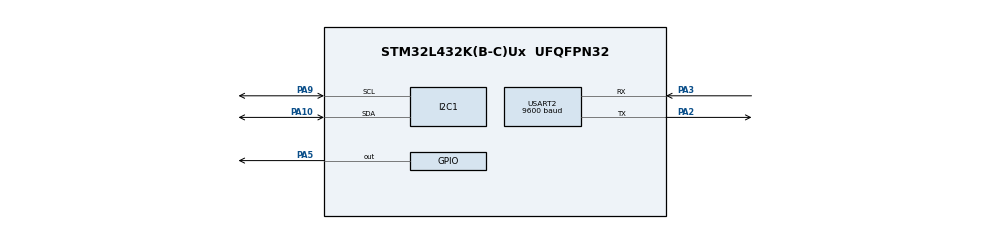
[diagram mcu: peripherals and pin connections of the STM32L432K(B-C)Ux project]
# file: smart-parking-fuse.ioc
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Mcu.Family=STM32L4
Mcu.Name=STM32L432K(B-C)Ux
Mcu.Package=UFQFPN32
NVIC.PriorityGroup=NVIC_PRIORITYGROUP_4
NVIC.USART2_IRQn=true\:0\:0\:false\:false\:true\:true\:true
PA10.Mode=I2C
PA10.Signal=I2C1_SDA
PA2.Mode=Asynchronous
PA2.Signal=USART2_TX
PA3.Mode=Asynchronous
PA3.Signal=USART2_RX
PA5.Signal=GPIO_Output
PA9.Mode=I2C
PA9.Signal=I2C1_SCL
ProjectManager.HeapSize=0x200
ProjectManager.StackSize=0x400
ProjectManager.TargetToolchain=Makefile
RCC.HSE_VALUE=8000000
RCC.HSI48_VALUE=48000000
RCC.HSI_VALUE=16000000
RCC.LSE_VALUE=32768
RCC.MSI_VALUE=4000000
RCC.VCOOutputFreq_Value=32000000
USART2.BaudRate=9600
USART2.VirtualMode-Asynchronous=VM_ASYNC
board=custom

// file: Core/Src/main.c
/**
  ******************************************************************************
  * @file           : main.c
  * @brief          : Main program body
  ******************************************************************************
  * @attention
  *
  * <h2><center>&copy; Copyright (c) 2021 STMicroelectronics.
  * All rights reserved.</center></h2>
  *
  * This software component is licensed by ST under BSD 3-Clause license,
  * the "License"; You may not use this file except in compliance with the
  * License. You may obtain a copy of the License at:
  *                        opensource.org/licenses/BSD-3-Clause
  *
  ******************************************************************************
  */
#include <stdio.h>
#include <string.h>

#include "main.h"
#include "uart.h"

#include <mma8451.h>

I2C_HandleTypeDef hi2c1;

UART_HandleTypeDef huart2;

void SystemClock_Config(void);
static void MX_GPIO_Init(void);
static void MX_I2C1_Init(void);
void MX_USART2_UART_Init(void);

void serial_write(uint8_t* msg, uint32_t size) {
    HAL_UART_Transmit(&huart2, msg, size, 100);
}

int main(void)
{
  /* Reset of all peripherals, Initializes the Flash interface and the Systick. */
  HAL_Init();

  /* Configure the system clock */
  SystemClock_Config();

  /* Initialize all configured peripherals */
  MX_GPIO_Init();
  MX_I2C1_Init();
  MX_USART2_UART_Init();

  setbuf(stdout, NULL);

  mma8451_t mma;
  memset(&mma, 0, sizeof(mma8451_t));

  HAL_GPIO_WritePin(GPIOA, GPIO_PIN_5, GPIO_PIN_SET);

  printf("Beginning default\n");

  uint8_t res = mma8451_begin_default(&mma, &hi2c1);

  while (1)
  {
    //HAL_UART_Transmit(&huart2, data, sizeof(data), 100);

    //HAL_StatusTypeDef status = HAL_I2C_IsDeviceReady(&hi2c1, MMA8451_DEFAULT_ADDRESS - 1, 64, HAL_MAX_DELAY);
    mma8451_read(&mma);
    //uint8_t data_r;
    //HAL_StatusTypeDef status = HAL_I2C_Mem_Read(&hi2c1, MMA8451_DEFAULT_ADDRESS, MMA8451_REG_WHOAMI, 1, &data_r, 1,
//                     10000);

    printf("Res %d\n", (int)res);
    //sprintf((char*)data, "x_g: %f y_g: %f z_g: %f\n", mma.x_g, mma.y_g, mma.z_g);
    HAL_Delay(100);
  }
}

void SystemClock_Config(void)
{
  RCC_OscInitTypeDef RCC_OscInitStruct = {0};
  RCC_ClkInitTypeDef RCC_ClkInitStruct = {0};
  RCC_PeriphCLKInitTypeDef PeriphClkInit = {0};

  /** Initializes the RCC Oscillators according to the specified parameters
  * in the RCC_OscInitTypeDef structure.
  */
  RCC_OscInitStruct.OscillatorType = RCC_OSCILLATORTYPE_MSI;
  RCC_OscInitStruct.MSIState = RCC_MSI_ON;
  RCC_OscInitStruct.MSICalibrationValue = 0;
  RCC_OscInitStruct.MSIClockRange = RCC_MSIRANGE_6;
  RCC_OscInitStruct.PLL.PLLState = RCC_PLL_NONE;
  if (HAL_RCC_OscConfig(&RCC_OscInitStruct) != HAL_OK)
  {
    Error_Handler();
  }
  /** Initializes the CPU, AHB and APB buses clocks
  */
  RCC_ClkInitStruct.ClockType = RCC_CLOCKTYPE_HCLK|RCC_CLOCKTYPE_SYSCLK
                              |RCC_CLOCKTYPE_PCLK1|RCC_CLOCKTYPE_PCLK2;
  RCC_ClkInitStruct.SYSCLKSource = RCC_SYSCLKSOURCE_MSI;
  RCC_ClkInitStruct.AHBCLKDivider = RCC_SYSCLK_DIV1;
  RCC_ClkInitStruct.APB1CLKDivider = RCC_HCLK_DIV1;
  RCC_ClkInitStruct.APB2CLKDivider = RCC_HCLK_DIV1;

  if (HAL_RCC_ClockConfig(&RCC_ClkInitStruct, FLASH_LATENCY_0) != HAL_OK)
  {
    Error_Handler();
  }
  PeriphClkInit.PeriphClockSelection = RCC_PERIPHCLK_USART2|RCC_PERIPHCLK_I2C1;
  PeriphClkInit.Usart2ClockSelection = RCC_USART2CLKSOURCE_PCLK1;
  PeriphClkInit.I2c1ClockSelection = RCC_I2C1CLKSOURCE_PCLK1;
  if (HAL_RCCEx_PeriphCLKConfig(&PeriphClkInit) != HAL_OK)
  {
    Error_Handler();
  }
  /** Configure the main internal regulator output voltage
  */
  if (HAL_PWREx_ControlVoltageScaling(PWR_REGULATOR_VOLTAGE_SCALE1) != HAL_OK)
  {
    Error_Handler();
  }
}

static void MX_I2C1_Init(void)
{
  hi2c1.Instance = I2C1;
  hi2c1.Init.Timing = 0x00000E14;
  hi2c1.Init.OwnAddress1 = 0;
  hi2c1.Init.AddressingMode = I2C_ADDRESSINGMODE_7BIT;
  hi2c1.Init.DualAddressMode = I2C_DUALADDRESS_DISABLE;
  hi2c1.Init.OwnAddress2 = 0;
  hi2c1.Init.OwnAddress2Masks = I2C_OA2_NOMASK;
  hi2c1.Init.GeneralCallMode = I2C_GENERALCALL_DISABLE;
  hi2c1.Init.NoStretchMode = I2C_NOSTRETCH_DISABLE;
  if (HAL_I2C_Init(&hi2c1) != HAL_OK)
  {
    Error_Handler();
  }
  /** Configure Analogue filter
  */
  if (HAL_I2CEx_ConfigAnalogFilter(&hi2c1, I2C_ANALOGFILTER_ENABLE) != HAL_OK)
  {
    Error_Handler();
  }
  /** Configure Digital filter
  */
  if (HAL_I2CEx_ConfigDigitalFilter(&hi2c1, 0) != HAL_OK)
  {
    Error_Handler();
  }
}

static void MX_GPIO_Init(void)
{
  GPIO_InitTypeDef GPIO_InitStruct = {0};

  /* GPIO Ports Clock Enable */
  __HAL_RCC_GPIOA_CLK_ENABLE();

  /*Configure GPIO pin Output Level */
  HAL_GPIO_WritePin(GPIOA, GPIO_PIN_5, GPIO_PIN_RESET);

  /*Configure GPIO pin : PA5 */
  GPIO_InitStruct.Pin = GPIO_PIN_5;
  GPIO_InitStruct.Mode = GPIO_MODE_OUTPUT_PP;
  GPIO_InitStruct.Pull = GPIO_NOPULL;
  GPIO_InitStruct.Speed = GPIO_SPEED_FREQ_LOW;
  HAL_GPIO_Init(GPIOA, &GPIO_InitStruct);

}

void Error_Handler(void)
{
  /* USER CODE BEGIN Error_Handler_Debug */
  /* User can add his own implementation to report the HAL error return state */
  __disable_irq();
  while (1)
  {
    uint8_t data[] = "Error!\n";
    //sprintf((char*)data, "x_g: %f y_g: %f z_g: %f\n", mma.x_g, mma.y_g, mma.z_g);
    HAL_UART_Transmit(&huart2, data, sizeof(data), 100);
  }
  /* USER CODE END Error_Handler_Debug */
}

/************************ (C) COPYRIGHT STMicroelectronics *****END OF FILE****/
